# BL808 register map
File version: 0.1
Registers are access not given, no defined reset value unless marked. A register's access mark holds for its fields unless they carry their own. Offsets are from the block's base; [hi:lo] are bit positions; {n}, {i} and the like mark numbered series.

## eFuse_Data0
Base 0x20056000
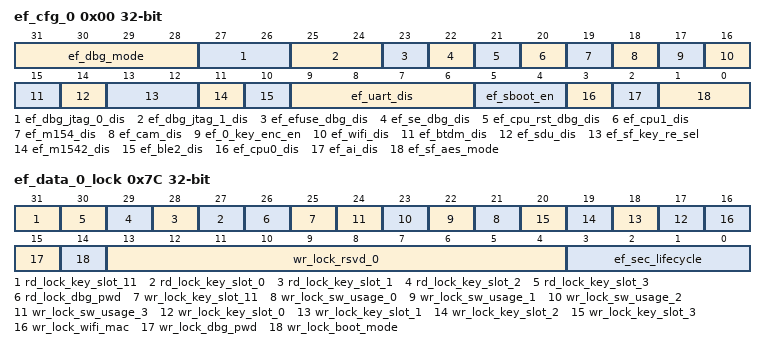
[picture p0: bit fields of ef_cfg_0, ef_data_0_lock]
0x00 ef_cfg_0 rw
  [31:28] ef_dbg_mode, [27:26] ef_dbg_jtag_0_dis, [25:24] ef_dbg_jtag_1_dis, [23] ef_efuse_dbg_dis, [22] ef_se_dbg_dis, [21] ef_cpu_rst_dbg_dis, [20] ef_cpu1_dis, [19] ef_m154_dis, [18] ef_cam_dis, [17] ef_0_key_enc_en, [16] ef_wifi_dis, [15] ef_btdm_dis, [14] ef_sdu_dis, [13:12] ef_sf_key_re_sel, [11] ef_m1542_dis, [10] ef_ble2_dis, [9:6] ef_uart_dis, [5:4] ef_sboot_en, [3] ef_cpu0_dis, [2] ef_ai_dis, [1:0] ef_sf_aes_mode
0x04 ef_dbg_pwd_low rw
  [31:0] ef_dbg_pwd_low
0x08 ef_dbg_pwd_high rw
  [31:0] ef_dbg_pwd_high
0x0C ef_dbg_pwd2_low rw
  [31:0] ef_dbg_pwd2_low
0x10 ef_dbg_pwd2_high rw
  [31:0] ef_dbg_pwd2_high
0x14 ef_wifi_mac_low rw
  [31:0] ef_wifi_mac_low
0x18 ef_wifi_mac_high rw
  [31:0] ef_wifi_mac_high
{0x1C+4i} ef_key_slot_0_w{i} rw (i=0..3)
  [31:0] ef_key_slot_0_w{i}
{0x2C+4i} ef_key_slot_1_w{i} rw (i=0..3)
  [31:0] ef_key_slot_1_w{i}
{0x3C+4i} ef_key_slot_2_w{i} rw (i=0..3)
  [31:0] ef_key_slot_2_w{i}
{0x4C+4i} ef_key_slot_3_w{i} rw (i=0..3)
  [31:0] ef_key_slot_3_w{i}
{0x5C+4i} ef_sw_usage_{i} rw (i=0..3)
  [31:0] ef_sw_usage_{i}
{0x6C+4i} ef_key_slot_11_w{i} rw (i=0..3)
  [31:0] ef_key_slot_11_w{i}
0x7C ef_data_0_lock rw
  [31] rd_lock_key_slot_11, [n+27] rd_lock_key_slot_{n} (n=0..3), [26] rd_lock_dbg_pwd, [25] wr_lock_key_slot_11, [n+21] wr_lock_sw_usage_{n} (n=0..3), [n+17] wr_lock_key_slot_{n} (n=0..3), [16] wr_lock_wifi_mac, [15] wr_lock_dbg_pwd, [14] wr_lock_boot_mode, [13:4] wr_lock_rsvd_0, [3:0] ef_sec_lifecycle

## eFuse_Data1
Base 0x20056000
{0x40+0x10*i} ef_key_slot_{i}_w0 rw (i=4..10)
  [31:0] ef_key_slot_{i}_w0
{0x44+0x10*i} ef_key_slot_{i}_w1 rw (i=4..10)
  [31:0] ef_key_slot_{i}_w1
{0x48+0x10*i} ef_key_slot_{i}_w2 rw (i=4..10)
  [31:0] ef_key_slot_{i}_w2
{0x4C+0x10*i} ef_key_slot_{i}_w3 rw (i=4..10)
  [31:0] ef_key_slot_{i}_w3
{0xF0+4i} ef_dat_1_rsvd_{i} rw (i=0..2)
  [31:0] ef_dat_1_rsvd_{i}
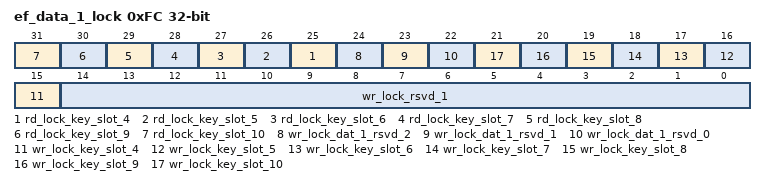
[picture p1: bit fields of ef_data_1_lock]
0xFC ef_data_1_lock rw
  [n+21] rd_lock_key_slot_{n} (n=4..10), [24] wr_lock_dat_1_rsvd_2, [23] wr_lock_dat_1_rsvd_1, [22] wr_lock_dat_1_rsvd_0, [n+11] wr_lock_key_slot_{n} (n=4..10), [14:0] wr_lock_rsvd_1

## SEC_DBG
Base 0x20003000
0x00 sd_chip_id_low ro
  [31:0] sd_chip_id_low
0x04 sd_chip_id_high ro
  [31:0] sd_chip_id_high
0x08 sd_dbg_pwd_low rw
  [31:0] sd_dbg_pwd_low
0x0C sd_dbg_pwd_high rw
  [31:0] sd_dbg_pwd_high
0x10 sd_dbg_pwd2_low rw
  [31:0] sd_dbg_pwd2_low
0x14 sd_dbg_pwd2_high rw
  [31:0] sd_dbg_pwd2_high
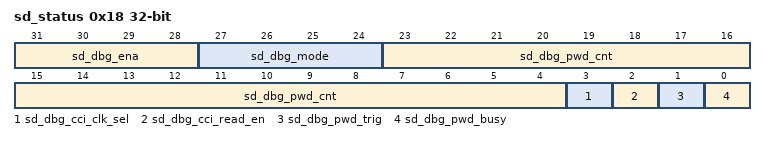
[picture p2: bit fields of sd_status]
0x18 sd_status access per field
  [31:28] sd_dbg_ena ro, [27:24] sd_dbg_mode ro, [23:4] sd_dbg_pwd_cnt ro, [3] sd_dbg_cci_clk_sel rw, [2] sd_dbg_cci_read_en rw, [1] sd_dbg_pwd_trig rw, [0] sd_dbg_pwd_busy ro
0x1C sd_dbg_reserved rw
  [31:0] sd_dbg_reserved

## ADC
Base 0x20002000
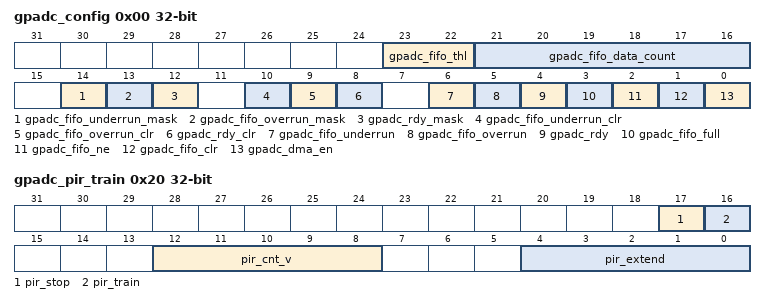
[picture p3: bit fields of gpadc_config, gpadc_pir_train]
0x00 gpadc_config
  [23:22] gpadc_fifo_thl rw — fifo threshold 2'b00: 1 data 2'b01: 4 data 2'b10: 8 data 2'b11: 16 data
  [21:16] gpadc_fifo_data_count ro — fifo data number
  [14] gpadc_fifo_underrun_mask rw — write 1 mask
  [13] gpadc_fifo_overrun_mask rw — write 1 mask
  [12] gpadc_rdy_mask rw — write 1 mask
  [10] gpadc_fifo_underrun_clr rw — Write 1 to clear flag
  [9] gpadc_fifo_overrun_clr rw — Write 1 to clear flag
  [8] gpadc_rdy_clr rw — Write 1 to clear flag
  [6] gpadc_fifo_underrun ro — FIFO underrun interrupt flag
  [5] gpadc_fifo_overrun ro — FIFO overrun interrupt flag
  [4] gpadc_rdy ro — Conversion data ready interrupt flag
  [3] gpadc_fifo_full ro — FIFO full flag
  [2] gpadc_fifo_ne ro — FIFO not empty flag
  [1] gpadc_fifo_clr write-once — FIFO clear signal
  [0] gpadc_dma_en rw — GPADC DMA enbale
0x04 gpadc_dma_rdata
  [25:0] gpadc_dma_rdata ro — GPADC finial conversion result stored in the FIFO
0x20 gpadc_pir_train
  [17] pir_stop ro — PIR Training End
  [16] pir_train rw — PIR Training Mode
  [12:8] pir_cnt_v ro — GPADC Record Extension Counter Value
  [4:0] pir_extend rw — GPADC Record Extension after PIR interrupt

## DAC
Base 0x20002040
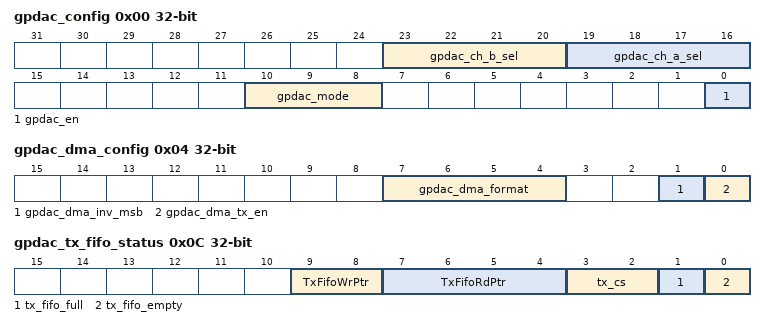
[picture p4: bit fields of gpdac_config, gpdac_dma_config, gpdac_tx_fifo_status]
0x00 gpdac_config
  [23:20] gpdac_ch_b_sel rw — Channel B Source Select 0: Reg 1: DMA 2: DMA + Filter 3: Sin Gen 4: A (The same as channel A) 5: ~A (Inverse of channel A)
  [19:16] gpdac_ch_a_sel rw — Channel A Source Select 0: Reg 1: DMA 2: DMA + Filter 3: Sin Gen
  [10:8] gpdac_mode rw — 0:32k, 1:16k, 3:8k, 4:512k(for DMA only)
  [0] gpdac_en rw — GPDAC enable
0x04 gpdac_dma_config
  [7:4] gpdac_dma_format rw — DMA TX format (Data 10-bit) 0: ([9:0]) {A0}, {A1}, {A2}… 1: ([25:16][9:0]) {B0,A0}, {B1,A1}, {B2,A2}… 2: ([25:16][9:0]) {A1,A0}, {A3,A2}, {A5,A4}… 4: ([15:6]) {A0}, {A1}, {A2}… 5: ([31:22][15:6]) {B0,A0}, {B1,A1}, {B2,A2}… 6: ([31:22][15:6]) {A1,A0}, {A3,A2}, {A5,A4}… 8: ([31:24][23:16][15:8][7:0]) {A3,A2,A1,A0}, {A7,A6,A5,A4}… 9: ([31:24][23:16][15:8][7:0]) {B1,B0,A1,A0}, {B3,B2,A3,A2}… 10: ([31:24][23:16][15:8][7:0]) {B1,A1,B0,A0}, {B3,A3,B2,A2}… 11: ([15:8][7:0]) {B0,A0}, {B1,A1}, {B2,A2}…
  [1] gpdac_dma_inv_msb rw — GPDAC DMA Data Inverse MSB
  [0] gpdac_dma_tx_en rw — GPDAC DMA TX enable
0x08 gpdac_dma_wdata wo
  [31:0] gpdac_dma_wdata — GPDAC DMA TX data
0x0C gpdac_tx_fifo_status
  [9:8] TxFifoWrPtr ro, [7:4] TxFifoRdPtr ro, [3:2] tx_cs ro, [1] tx_fifo_full ro, [0] tx_fifo_empty ro
